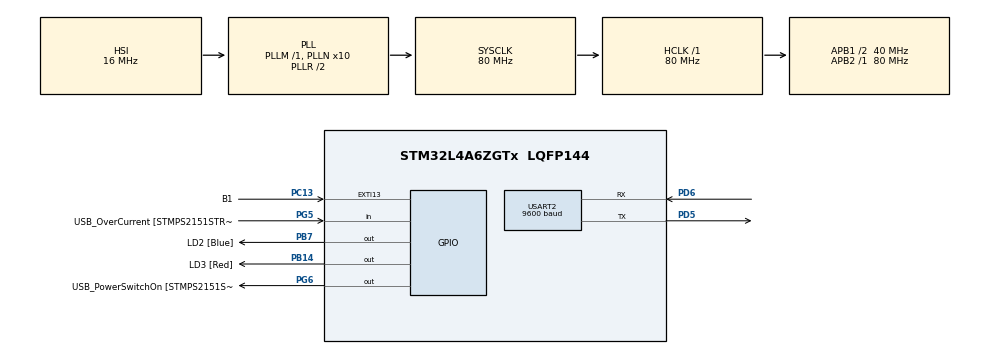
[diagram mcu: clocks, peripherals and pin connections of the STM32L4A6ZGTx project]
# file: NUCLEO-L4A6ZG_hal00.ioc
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Mcu.Family=STM32L4
Mcu.Name=STM32L4A6ZGTx
Mcu.Package=LQFP144
NVIC.PriorityGroup=NVIC_PRIORITYGROUP_4
NVIC.TIM6_DAC_IRQn=true\:0\:0\:false\:false\:true\:true\:true\:true
PA10.GPIO_Label=USB_ID
PA10.Signal=USB_OTG_FS_ID
PA11.GPIO_Label=USB_DM
PA11.Signal=USB_OTG_FS_DM
PA12.GPIO_Label=USB_DP
PA12.Signal=USB_OTG_FS_DP
PA13\ (JTMS/SWDIO).GPIO_Label=TMS
PA13\ (JTMS/SWDIO).Mode=Trace_Asynchronous_SW
PA13\ (JTMS/SWDIO).Signal=SYS_JTMS-SWDIO
PA14\ (JTCK/SWCLK).GPIO_Label=TCK
PA14\ (JTCK/SWCLK).Mode=Trace_Asynchronous_SW
PA14\ (JTCK/SWCLK).Signal=SYS_JTCK-SWCLK
PA8.GPIO_Label=USB_SOF [TP1]
PA8.Signal=USB_OTG_FS_SOF
PA9.GPIO_Label=USB_VBUS
PA9.Signal=USB_OTG_FS_VBUS
PB14.GPIO_Label=LD3 [Red]
PB14.Signal=GPIO_Output
PB3\ (JTDO/TRACESWO).GPIO_Label=SWO
PB3\ (JTDO/TRACESWO).Mode=Trace_Asynchronous_SW
PB3\ (JTDO/TRACESWO).Signal=SYS_JTDO-SWO
PB7.GPIO_Label=LD2 [Blue]
PB7.Signal=GPIO_Output
PC13.GPIO_Label=B1
PC13.Signal=GPXTI13
PC14-OSC32_IN\ (PC14).Signal=RCC_OSC32_IN
PC15-OSC32_OUT\ (PC15).Signal=RCC_OSC32_OUT
PD5.Mode=Asynchronous
PD5.Signal=USART2_TX
PD6.Mode=Asynchronous
PD6.Signal=USART2_RX
PG5.GPIO_Label=USB_OverCurrent [STMPS2151STR_FAULT]
PG5.Signal=GPIO_Input
PG6.GPIO_Label=USB_PowerSwitchOn [STMPS2151STR_EN]
PG6.Signal=GPIO_Output
PG7.GPIO_Label=STLK_RX [STM32F103CBT6_PA3]
PG7.Signal=LPUART1_TX
PG8.GPIO_Label=STLK_TX [STM32F103CBT6_PA2]
PG8.Signal=LPUART1_RX
PH1-OSC_OUT\ (PH1).Signal=RCC_OSC_OUT
ProjectManager.HeapSize=0x200
ProjectManager.StackSize=0x400
ProjectManager.TargetToolchain=STM32CubeIDE
RCC.ADCFreq_Value=64000000
RCC.AHBFreq_Value=80000000
RCC.APB1CLKDivider=RCC_HCLK_DIV2
RCC.APB1Freq_Value=40000000
RCC.APB1TimFreq_Value=80000000
RCC.APB2Freq_Value=80000000
RCC.APB2TimFreq_Value=80000000
RCC.CortexFreq_Value=80000000
RCC.HCLKFreq_Value=80000000
RCC.HSE_VALUE=8000000
RCC.HSI48_VALUE=48000000
RCC.HSI_VALUE=16000000
RCC.LSE_VALUE=32768
RCC.MSI_VALUE=4000000
RCC.PLLN=10
RCC.PLLSourceVirtual=RCC_PLLSOURCE_HSI
RCC.SYSCLKFreq_VALUE=80000000
RCC.SYSCLKSource=RCC_SYSCLKSOURCE_PLLCLK
RCC.USBFreq_Value=64000000
RCC.VCOOutputFreq_Value=160000000
TIM6.AutoReloadPreload=TIM_AUTORELOAD_PRELOAD_ENABLE
TIM6.Period=1250-1
TIM6.Prescaler=64000-1
USART2.BaudRate=9600
USART2.VirtualMode-Asynchronous=VM_ASYNC
VP_TIM6_VS_ClockSourceINT.Mode=Enable_Timer
board=NUCLEO-L4A6ZG

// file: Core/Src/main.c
/* USER CODE BEGIN Header */
/**
  ******************************************************************************
  * @file           : main.c
  * @brief          : Main program body
  ******************************************************************************
  * @attention
  *
  * Copyright (c) 2024 STMicroelectronics.
  * All rights reserved.
  *
  * This software is licensed under terms that can be found in the LICENSE file
  * in the root directory of this software component.
  * If no LICENSE file comes with this software, it is provided AS-IS.
  *
  ******************************************************************************
  */
/* USER CODE END Header */
#include "main.h"

TIM_HandleTypeDef htim6;

UART_HandleTypeDef huart2;

void SystemClock_Config(void);
static void MX_GPIO_Init(void);
static void MX_TIM6_Init(void);
static void MX_USART2_UART_Init(void);

/* USER CODE BEGIN 0 */
void HAL_TIM_PeriodElapsedCallback(TIM_HandleTypeDef *htim)
{
	if(htim == &htim6){
		// LED2出力を反転させる
		HAL_GPIO_TogglePin(GPIOB, LD2_Pin);
	}
}
/* USER CODE END 0 */

int main(void)
{

  /* USER CODE BEGIN 1 */
	uint8_t u8_DataSw;
	uint8_t u8_DataUart;
	HAL_StatusTypeDef en_StateUart;
  /* USER CODE END 1 */

  /* MCU Configuration--------------------------------------------------------*/

  /* Reset of all peripherals, Initializes the Flash interface and the Systick. */
  HAL_Init();

  /* Configure the system clock */
  SystemClock_Config();

  /* Initialize all configured peripherals */
  MX_GPIO_Init();
  MX_TIM6_Init();
  MX_USART2_UART_Init();
  /* USER CODE BEGIN 2 */
	// TIM6を開始する
	HAL_TIM_Base_Start_IT(&htim6);
  /* USER CODE END 2 */

  /* Infinite loop */
  /* USER CODE BEGIN WHILE */
	while (1) {
		// ユーザーSW入力を読み込む
		u8_DataSw = HAL_GPIO_ReadPin(B1_GPIO_Port, B1_Pin);
		// ユーザーSW入力で、LED3出力を更新する
		HAL_GPIO_WritePin(GPIOB, LD3_Pin, u8_DataSw);

		// UART2受信を確認する
		en_StateUart = HAL_UART_Receive(&huart2, &u8_DataUart, 1, 0);
		// UART2受信があれば、UART2送信を行う
		if (en_StateUart == HAL_OK) {
			HAL_UART_Transmit(&huart2, &u8_DataUart, 1, 0);
		}
    /* USER CODE END WHILE */

	}
}

void SystemClock_Config(void)
{
  RCC_OscInitTypeDef RCC_OscInitStruct = {0};
  RCC_ClkInitTypeDef RCC_ClkInitStruct = {0};

  /** Configure the main internal regulator output voltage
  */
  if (HAL_PWREx_ControlVoltageScaling(PWR_REGULATOR_VOLTAGE_SCALE1) != HAL_OK)
  {
    Error_Handler();
  }

  /** Initializes the RCC Oscillators according to the specified parameters
  * in the RCC_OscInitTypeDef structure.
  */
  RCC_OscInitStruct.OscillatorType = RCC_OSCILLATORTYPE_HSI;
  RCC_OscInitStruct.HSIState = RCC_HSI_ON;
  RCC_OscInitStruct.HSICalibrationValue = RCC_HSICALIBRATION_DEFAULT;
  RCC_OscInitStruct.PLL.PLLState = RCC_PLL_ON;
  RCC_OscInitStruct.PLL.PLLSource = RCC_PLLSOURCE_HSI;
  RCC_OscInitStruct.PLL.PLLM = 1;
  RCC_OscInitStruct.PLL.PLLN = 10;
  RCC_OscInitStruct.PLL.PLLP = RCC_PLLP_DIV2;
  RCC_OscInitStruct.PLL.PLLQ = RCC_PLLQ_DIV2;
  RCC_OscInitStruct.PLL.PLLR = RCC_PLLR_DIV2;
  if (HAL_RCC_OscConfig(&RCC_OscInitStruct) != HAL_OK)
  {
    Error_Handler();
  }

  /** Initializes the CPU, AHB and APB buses clocks
  */
  RCC_ClkInitStruct.ClockType = RCC_CLOCKTYPE_HCLK|RCC_CLOCKTYPE_SYSCLK
                              |RCC_CLOCKTYPE_PCLK1|RCC_CLOCKTYPE_PCLK2;
  RCC_ClkInitStruct.SYSCLKSource = RCC_SYSCLKSOURCE_PLLCLK;
  RCC_ClkInitStruct.AHBCLKDivider = RCC_SYSCLK_DIV1;
  RCC_ClkInitStruct.APB1CLKDivider = RCC_HCLK_DIV2;
  RCC_ClkInitStruct.APB2CLKDivider = RCC_HCLK_DIV1;

  if (HAL_RCC_ClockConfig(&RCC_ClkInitStruct, FLASH_LATENCY_4) != HAL_OK)
  {
    Error_Handler();
  }
}

static void MX_TIM6_Init(void)
{

  TIM_MasterConfigTypeDef sMasterConfig = {0};

  htim6.Instance = TIM6;
  htim6.Init.Prescaler = 64000-1;
  htim6.Init.CounterMode = TIM_COUNTERMODE_UP;
  htim6.Init.Period = 1250-1;
  htim6.Init.AutoReloadPreload = TIM_AUTORELOAD_PRELOAD_ENABLE;
  if (HAL_TIM_Base_Init(&htim6) != HAL_OK)
  {
    Error_Handler();
  }
  sMasterConfig.MasterOutputTrigger = TIM_TRGO_RESET;
  sMasterConfig.MasterSlaveMode = TIM_MASTERSLAVEMODE_DISABLE;
  if (HAL_TIMEx_MasterConfigSynchronization(&htim6, &sMasterConfig) != HAL_OK)
  {
    Error_Handler();
  }

}

static void MX_USART2_UART_Init(void)
{

  huart2.Instance = USART2;
  huart2.Init.BaudRate = 9600;
  huart2.Init.WordLength = UART_WORDLENGTH_8B;
  huart2.Init.StopBits = UART_STOPBITS_1;
  huart2.Init.Parity = UART_PARITY_NONE;
  huart2.Init.Mode = UART_MODE_TX_RX;
  huart2.Init.HwFlowCtl = UART_HWCONTROL_NONE;
  huart2.Init.OverSampling = UART_OVERSAMPLING_16;
  huart2.Init.OneBitSampling = UART_ONE_BIT_SAMPLE_DISABLE;
  huart2.AdvancedInit.AdvFeatureInit = UART_ADVFEATURE_NO_INIT;
  if (HAL_UART_Init(&huart2) != HAL_OK)
  {
    Error_Handler();
  }

}

static void MX_GPIO_Init(void)
{
  GPIO_InitTypeDef GPIO_InitStruct = {0};

  /* GPIO Ports Clock Enable */
  __HAL_RCC_GPIOC_CLK_ENABLE();
  __HAL_RCC_GPIOH_CLK_ENABLE();
  __HAL_RCC_GPIOB_CLK_ENABLE();
  __HAL_RCC_GPIOG_CLK_ENABLE();
  HAL_PWREx_EnableVddIO2();
  __HAL_RCC_GPIOA_CLK_ENABLE();
  __HAL_RCC_GPIOD_CLK_ENABLE();

  /*Configure GPIO pin Output Level */
  HAL_GPIO_WritePin(GPIOB, LD3_Pin|LD2_Pin, GPIO_PIN_RESET);

  /*Configure GPIO pin Output Level */
  HAL_GPIO_WritePin(USB_PowerSwitchOn_GPIO_Port, USB_PowerSwitchOn_Pin, GPIO_PIN_RESET);

  /*Configure GPIO pin : B1_Pin */
  GPIO_InitStruct.Pin = B1_Pin;
  GPIO_InitStruct.Mode = GPIO_MODE_IT_RISING;
  GPIO_InitStruct.Pull = GPIO_NOPULL;
  HAL_GPIO_Init(B1_GPIO_Port, &GPIO_InitStruct);

  /*Configure GPIO pins : LD3_Pin LD2_Pin */
  GPIO_InitStruct.Pin = LD3_Pin|LD2_Pin;
  GPIO_InitStruct.Mode = GPIO_MODE_OUTPUT_PP;
  GPIO_InitStruct.Pull = GPIO_NOPULL;
  GPIO_InitStruct.Speed = GPIO_SPEED_FREQ_LOW;
  HAL_GPIO_Init(GPIOB, &GPIO_InitStruct);

  /*Configure GPIO pin : USB_OverCurrent_Pin */
  GPIO_InitStruct.Pin = USB_OverCurrent_Pin;
  GPIO_InitStruct.Mode = GPIO_MODE_INPUT;
  GPIO_InitStruct.Pull = GPIO_NOPULL;
  HAL_GPIO_Init(USB_OverCurrent_GPIO_Port, &GPIO_InitStruct);

  /*Configure GPIO pin : USB_PowerSwitchOn_Pin */
  GPIO_InitStruct.Pin = USB_PowerSwitchOn_Pin;
  GPIO_InitStruct.Mode = GPIO_MODE_OUTPUT_PP;
  GPIO_InitStruct.Pull = GPIO_NOPULL;
  GPIO_InitStruct.Speed = GPIO_SPEED_FREQ_LOW;
  HAL_GPIO_Init(USB_PowerSwitchOn_GPIO_Port, &GPIO_InitStruct);

  /*Configure GPIO pins : STLK_RX_Pin STLK_TX_Pin */
  GPIO_InitStruct.Pin = STLK_RX_Pin|STLK_TX_Pin;
  GPIO_InitStruct.Mode = GPIO_MODE_AF_PP;
  GPIO_InitStruct.Pull = GPIO_NOPULL;
  GPIO_InitStruct.Speed = GPIO_SPEED_FREQ_VERY_HIGH;
  GPIO_InitStruct.Alternate = GPIO_AF8_LPUART1;
  HAL_GPIO_Init(GPIOG, &GPIO_InitStruct);

  /*Configure GPIO pins : USB_SOF_Pin USB_ID_Pin USB_DM_Pin USB_DP_Pin */
  GPIO_InitStruct.Pin = USB_SOF_Pin|USB_ID_Pin|USB_DM_Pin|USB_DP_Pin;
  GPIO_InitStruct.Mode = GPIO_MODE_AF_PP;
  GPIO_InitStruct.Pull = GPIO_NOPULL;
  GPIO_InitStruct.Speed = GPIO_SPEED_FREQ_VERY_HIGH;
  GPIO_InitStruct.Alternate = GPIO_AF10_OTG_FS;
  HAL_GPIO_Init(GPIOA, &GPIO_InitStruct);

}

void Error_Handler(void)
{
  __disable_irq();
  while (1)
  {
  }
}
